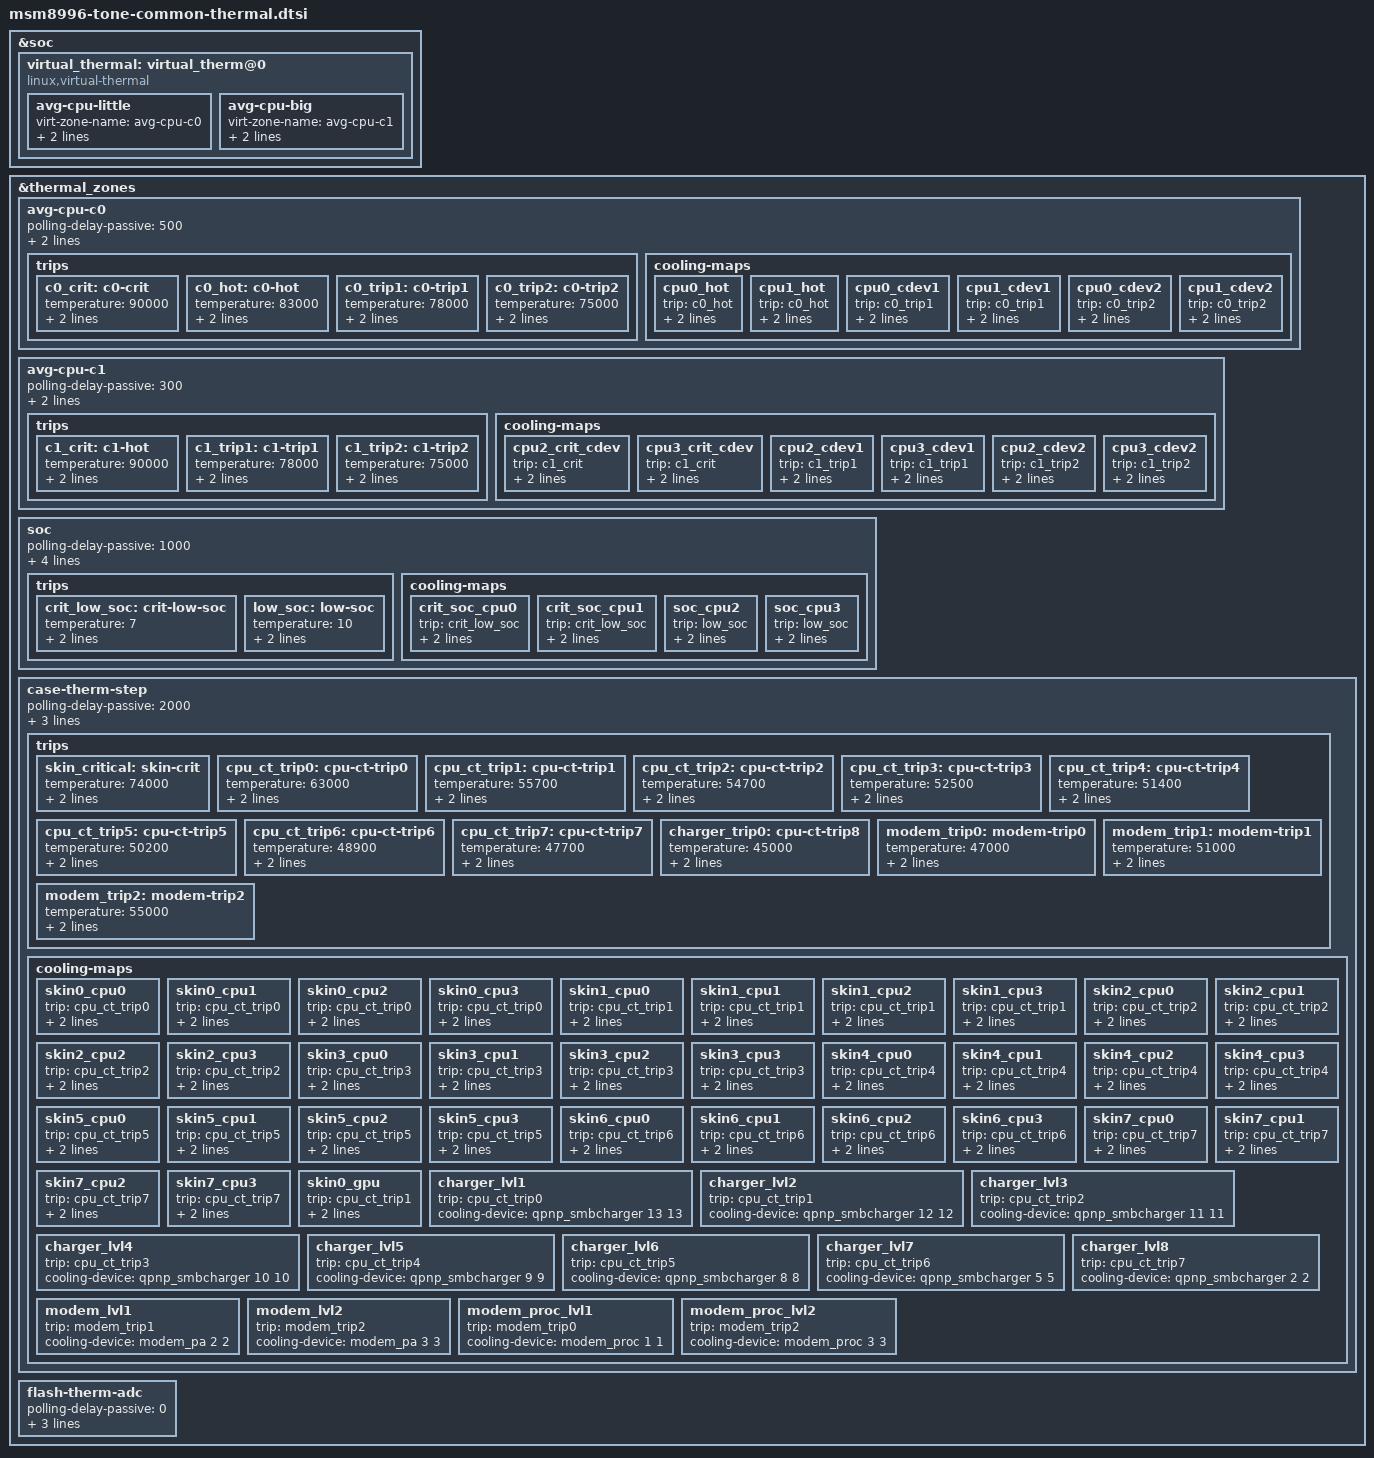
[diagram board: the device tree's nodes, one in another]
/* arch/arm64/boot/dts/qcom/msm8996-tone-common-thermal.dtsi
 *
 * This program is free software; you can redistribute it and/or modify
 * it under the terms of the GNU General Public License version 2 and
 * only version 2 as published by the Free Software Foundation.
 *
 * This program is distributed in the hope that it will be useful,
 * but WITHOUT ANY WARRANTY; without even the implied warranty of
 * MERCHANTABILITY or FITNESS FOR A PARTICULAR PURPOSE.  See the
 * GNU General Public License for more details.
 */
/*
 * Copyright (C) 2018 AngeloGioacchino Del Regno <kholk11@gmail.com>
 *
 * This program is free software; you can redistribute it and/or modify
 * it under the terms of the GNU General Public License version 2, as
 * published by the Free Software Foundation.
 */

&soc {
	virtual_thermal: virtual_therm@0 {
		compatible = "linux,virtual-thermal";
		status = "ok";
	};
};

&virtual_thermal {
	avg-cpu-little {
		virt-zone-name = "avg-cpu-c0";
		thermal-sensor-names = "cpu0-usr", "cpu1-usr";
		aggregation-logic = <0>; /* WEIGHTED_AVG */
	};
	avg-cpu-big {
		virt-zone-name = "avg-cpu-c1";
		thermal-sensor-names = "cpu2-usr", "cpu3-usr";
		aggregation-logic = <0>; /* WEIGHTED_AVG */
	};
};

&thermal_zones {
	avg-cpu-c0 {
		polling-delay-passive = <500>;
		polling-delay = <750>;
		thermal-governor = "step_wise";
		trips {
			c0_crit: c0-crit {
				temperature = <90000>;
				hysteresis = <4000>;
				type = "critical";
			};

			c0_hot: c0-hot {
				temperature = <83000>;
				hysteresis = <4000>;
				type = "hot";
			};

			c0_trip1: c0-trip1 {
				temperature = <78000>;
				hysteresis = <3000>;
				type = "passive";
				
			};

			c0_trip2: c0-trip2 {
				temperature = <75000>;
				hysteresis = <4000>;
				type = "passive";
				
			};
		};

		cooling-maps {
			/* Throttle from FMAX to 403.2MHz */
			cpu0_hot {
				trip = <&c0_hot>;
				cooling-device =
					<&CPU0 THERMAL_NO_LIMIT
						(THERMAL_MAX_LIMIT-3)>;
			};
			cpu1_hot {
				trip = <&c0_hot>;
				cooling-device =
					<&CPU1 THERMAL_NO_LIMIT
						(THERMAL_MAX_LIMIT-3)>;
			};

			/* Throttle from FMAX to 1267.2MHz */
			cpu0_cdev1 {
				trip = <&c0_trip1>;
				cooling-device =
					<&CPU0 THERMAL_NO_LIMIT
						(THERMAL_MAX_LIMIT-14)>;
			};
			cpu1_cdev1 {
				trip = <&c0_trip1>;
				cooling-device =
					<&CPU1 THERMAL_NO_LIMIT
						(THERMAL_MAX_LIMIT-14)>;
			};

			/* Throttle from FMAX to 1420.8MHz */
			cpu0_cdev2 {
				trip = <&c0_trip2>;
				cooling-device =
					<&CPU0 THERMAL_NO_LIMIT
						(THERMAL_MAX_LIMIT-16)>;
			};
			cpu1_cdev2 {
				trip = <&c0_trip2>;
				cooling-device =
					<&CPU1 THERMAL_NO_LIMIT
						(THERMAL_MAX_LIMIT-16)>;
			};

		};
	};

	avg-cpu-c1 {
		polling-delay-passive = <300>;
		polling-delay = <500>;
		thermal-governor = "step_wise";
		trips {
			c1_crit: c1-hot {
				temperature = <90000>;
				hysteresis = <4000>;
				type = "hot";
			};

			c1_trip1: c1-trip1 {
				temperature = <78000>;
				hysteresis = <3000>;
				type = "passive";
				
			};

			c1_trip2: c1-trip2 {
				temperature = <75000>;
				hysteresis = <4000>;
				type = "passive";
				
			};
		};

		cooling-maps {
			/* Temperature is critical: Shut down C1 */
			cpu2_crit_cdev {
				trip = <&c1_crit>;
				cooling-device =
					<&CPU2 THERMAL_MAX_LIMIT
						THERMAL_MAX_LIMIT>;
			};
			cpu3_crit_cdev {
				trip = <&c1_crit>;
				cooling-device =
					<&CPU3 THERMAL_MAX_LIMIT
						THERMAL_MAX_LIMIT>;
			};

			/* Throttle from FMAX to 1113.6MHz */
			cpu2_cdev1 {
				trip = <&c1_trip1>;
				cooling-device =
					<&CPU2 THERMAL_NO_LIMIT
						(THERMAL_MAX_LIMIT-12)>;
			};
			cpu3_cdev1 {
				trip = <&c1_trip1>;
				cooling-device =
					<&CPU3 THERMAL_NO_LIMIT
						(THERMAL_MAX_LIMIT-12)>;
			};

			/* Throttle from FMAX to 883.2MHz */
			cpu2_cdev2 {
				trip = <&c1_trip2>;
				cooling-device =
					<&CPU2 THERMAL_NO_LIMIT
						(THERMAL_MAX_LIMIT-9)>;
			};
			cpu3_cdev2 {
				trip = <&c1_trip2>;
				cooling-device =
					<&CPU3 THERMAL_NO_LIMIT
						(THERMAL_MAX_LIMIT-9)>;
			};
		};
	};

	soc {
		polling-delay-passive = <1000>;
		polling-delay = <0>;
		thermal-governor = "low_limits_cap";
		thermal-sensors = <&bcl_sensor 2>;
		tracks-low;

		trips {
			crit_low_soc: crit-low-soc {
				temperature = <7>;
				hysteresis = <0>;
				type = "passive";
			};
			low_soc: low-soc {
				temperature = <10>;
				hysteresis = <0>;
				type = "passive";
			};
		};

		cooling-maps {
			/* Throttle C0 from FMAX to 1190.4MHz */
			crit_soc_cpu0 {
				trip = <&crit_low_soc>;
				cooling-device =
					<&CPU0 THERMAL_NO_LIMIT
						(THERMAL_MAX_LIMIT-12)>;
			};
			crit_soc_cpu1 {
				trip = <&crit_low_soc>;
				cooling-device =
					<&CPU1 THERMAL_NO_LIMIT
						(THERMAL_MAX_LIMIT-12)>;
			};

			/* Shut down C1 */
			soc_cpu2 {
				trip = <&low_soc>;
				cooling-device =
					<&CPU2 THERMAL_MAX_LIMIT
						THERMAL_MAX_LIMIT>;
			};
			soc_cpu3 {
				trip = <&low_soc>;
				cooling-device =
					<&CPU3 THERMAL_MAX_LIMIT
						THERMAL_MAX_LIMIT>;
			};
		};
	};

	case-therm-step {
		polling-delay-passive = <2000>;
		polling-delay = <0>;
		thermal-sensors = <&pm8994_vadc 0x74>;
		thermal-governor = "step_wise";

		trips {
			skin_critical: skin-crit {
				temperature = <74000>;
				hysteresis = <2000>;
				type = "critical";
			};

			cpu_ct_trip0: cpu-ct-trip0 {
				temperature = <63000>;
				hysteresis = <3000>;
				type = "passive";
			};
			cpu_ct_trip1: cpu-ct-trip1 {
				temperature = <55700>;
				hysteresis = <1000>;
				type = "passive";
			};
			cpu_ct_trip2: cpu-ct-trip2 {
				temperature = <54700>;
				hysteresis = <1200>;
				type = "passive";
			};
			cpu_ct_trip3: cpu-ct-trip3 {
				temperature = <52500>;
				hysteresis = <1100>;
				type = "passive";
			};
			cpu_ct_trip4: cpu-ct-trip4 {
				temperature = <51400>;
				hysteresis = <1200>;
				type = "passive";
			};
			cpu_ct_trip5: cpu-ct-trip5 {
				temperature = <50200>;
				hysteresis = <300>;
				type = "passive";
			};
			cpu_ct_trip6: cpu-ct-trip6 {
				temperature = <48900>;
				hysteresis = <1200>;
				type = "passive";
			};
			cpu_ct_trip7: cpu-ct-trip7 {
				temperature = <47700>;
				hysteresis = <2700>;
				type = "passive";
			};

			charger_trip0: cpu-ct-trip8 {
				temperature = <45000>;
				hysteresis = <3000>;
				type = "passive";
			};

			modem_trip0: modem-trip0 {
				temperature = <47000>;
				hysteresis = <2000>;
				type = "passive";
			};
			modem_trip1: modem-trip1 {
				temperature = <51000>;
				hysteresis = <3000>;
				type = "passive";
			};
			modem_trip2: modem-trip2 {
				temperature = <55000>;
				hysteresis = <4000>;
				type = "passive";
			};
		};

		cooling-maps {
			/* Throttle from FMAX to 307.2MHz */
			skin0_cpu0 {
				trip = <&cpu_ct_trip0>;
				cooling-device = <&CPU0 THERMAL_NO_LIMIT
							(THERMAL_MAX_LIMIT-1)>;
			};
			skin0_cpu1 {
				trip = <&cpu_ct_trip0>;
				cooling-device = <&CPU1 THERMAL_NO_LIMIT
							(THERMAL_MAX_LIMIT-1)>;
			};
			/* Reaching critical: shutdown C1 */
			skin0_cpu2 {
				trip = <&cpu_ct_trip0>;
				cooling-device = <&CPU2 THERMAL_NO_LIMIT
							THERMAL_MAX_LIMIT>;
			};
			skin0_cpu3 {
				trip = <&cpu_ct_trip0>;
				cooling-device = <&CPU3 THERMAL_NO_LIMIT
							THERMAL_MAX_LIMIT>;
			};

			/* Throttle from FMAX to 307.2MHz */
			skin1_cpu0 {
				trip = <&cpu_ct_trip1>;
				cooling-device = <&CPU0 THERMAL_NO_LIMIT
							(THERMAL_MAX_LIMIT-1)>;
			};
			skin1_cpu1 {
				trip = <&cpu_ct_trip1>;
				cooling-device = <&CPU1 THERMAL_NO_LIMIT
							(THERMAL_MAX_LIMIT-1)>;
			};
			skin1_cpu2 {
				trip = <&cpu_ct_trip1>;
				cooling-device = <&CPU2 THERMAL_NO_LIMIT
							(THERMAL_MAX_LIMIT-1)>;
			};
			skin1_cpu3 {
				trip = <&cpu_ct_trip1>;
				cooling-device = <&CPU3 THERMAL_NO_LIMIT
							(THERMAL_MAX_LIMIT-1)>;
			};

			/* Throttle from FMAX to 480MHz */
			skin2_cpu0 {
				trip = <&cpu_ct_trip2>;
				cooling-device = <&CPU0 THERMAL_NO_LIMIT
							(THERMAL_MAX_LIMIT-4)>;
			};
			skin2_cpu1 {
				trip = <&cpu_ct_trip2>;
				cooling-device = <&CPU1 THERMAL_NO_LIMIT
							(THERMAL_MAX_LIMIT-4)>;
			};
			skin2_cpu2 {
				trip = <&cpu_ct_trip2>;
				cooling-device = <&CPU2 THERMAL_NO_LIMIT
							(THERMAL_MAX_LIMIT-4)>;
			};
			skin2_cpu3 {
				trip = <&cpu_ct_trip2>;
				cooling-device = <&CPU3 THERMAL_NO_LIMIT
							(THERMAL_MAX_LIMIT-4)>;
			};

			/* Throttle from FMAX to 883.2MHz */
			skin3_cpu0 {
				trip = <&cpu_ct_trip3>;
				cooling-device = <&CPU0 THERMAL_NO_LIMIT
							(THERMAL_MAX_LIMIT-9)>;
			};
			skin3_cpu1 {
				trip = <&cpu_ct_trip3>;
				cooling-device = <&CPU1 THERMAL_NO_LIMIT
							(THERMAL_MAX_LIMIT-9)>;
			};
			skin3_cpu2 {
				trip = <&cpu_ct_trip3>;
				cooling-device = <&CPU2 THERMAL_NO_LIMIT
							(THERMAL_MAX_LIMIT-9)>;
			};
			skin3_cpu3 {
				trip = <&cpu_ct_trip3>;
				cooling-device = <&CPU3 THERMAL_NO_LIMIT
							(THERMAL_MAX_LIMIT-9)>;
			};

			/* Throttle from FMAX to 1017.6MHz */
			skin4_cpu0 {
				trip = <&cpu_ct_trip4>;
				cooling-device = <&CPU0 THERMAL_NO_LIMIT
							(THERMAL_MAX_LIMIT-11)>;
			};
			skin4_cpu1 {
				trip = <&cpu_ct_trip4>;
				cooling-device = <&CPU1 THERMAL_NO_LIMIT
							(THERMAL_MAX_LIMIT-11)>;
			};
			skin4_cpu2 {
				trip = <&cpu_ct_trip4>;
				cooling-device = <&CPU2 THERMAL_NO_LIMIT
							(THERMAL_MAX_LIMIT-11)>;
			};
			skin4_cpu3 {
				trip = <&cpu_ct_trip4>;
				cooling-device = <&CPU3 THERMAL_NO_LIMIT
							(THERMAL_MAX_LIMIT-11)>;
			};

			/* Throttle from FMAX to 1113.6MHz */
			skin5_cpu0 {
				trip = <&cpu_ct_trip5>;
				cooling-device = <&CPU0 THERMAL_NO_LIMIT
							(THERMAL_MAX_LIMIT-12)>;
			};
			skin5_cpu1 {
				trip = <&cpu_ct_trip5>;
				cooling-device = <&CPU1 THERMAL_NO_LIMIT
							(THERMAL_MAX_LIMIT-12)>;
			};
			skin5_cpu2 {
				trip = <&cpu_ct_trip5>;
				cooling-device = <&CPU2 THERMAL_NO_LIMIT
							(THERMAL_MAX_LIMIT-12)>;
			};
			skin5_cpu3 {
				trip = <&cpu_ct_trip5>;
				cooling-device = <&CPU3 THERMAL_NO_LIMIT
							(THERMAL_MAX_LIMIT-12)>;
			};

			/* Throttle from FMAX to 1344MHz */
			skin6_cpu0 {
				trip = <&cpu_ct_trip6>;
				cooling-device = <&CPU0 THERMAL_NO_LIMIT
							(THERMAL_MAX_LIMIT-15)>;
			};
			skin6_cpu1 {
				trip = <&cpu_ct_trip6>;
				cooling-device = <&CPU1 THERMAL_NO_LIMIT
							(THERMAL_MAX_LIMIT-15)>;
			};
			skin6_cpu2 {
				trip = <&cpu_ct_trip6>;
				cooling-device = <&CPU2 THERMAL_NO_LIMIT
							(THERMAL_MAX_LIMIT-15)>;
			};
			skin6_cpu3 {
				trip = <&cpu_ct_trip6>;
				cooling-device = <&CPU3 THERMAL_NO_LIMIT
							(THERMAL_MAX_LIMIT-15)>;
			};

			/* Throttle from C0-C1 FMAX to 1459.2-1497.6MHz */
			skin7_cpu0 {
				trip = <&cpu_ct_trip7>;
				cooling-device = <&CPU0 THERMAL_NO_LIMIT
							(THERMAL_MAX_LIMIT-17)>;
			};
			skin7_cpu1 {
				trip = <&cpu_ct_trip7>;
				cooling-device = <&CPU1 THERMAL_NO_LIMIT
							(THERMAL_MAX_LIMIT-17)>;
			};
			skin7_cpu2 {
				trip = <&cpu_ct_trip7>;
				cooling-device = <&CPU2 THERMAL_NO_LIMIT
							(THERMAL_MAX_LIMIT-17)>;
			};
			skin7_cpu3 {
				trip = <&cpu_ct_trip7>;
				cooling-device = <&CPU3 THERMAL_NO_LIMIT
							(THERMAL_MAX_LIMIT-17)>;
			};

			/* Throttle from FMAX to 133MHz */
			skin0_gpu {
				trip = <&cpu_ct_trip1>;
				cooling-device = <&msm_gpu THERMAL_NO_LIMIT
							   (THERMAL_MAX_LIMIT-1)>;
			};

			/* Battery charging current limit */
			charger_lvl1 {
				trip = <&cpu_ct_trip0>;
				cooling-device = <&qpnp_smbcharger 13 13>;
			};
			charger_lvl2 {
				trip = <&cpu_ct_trip1>;
				cooling-device = <&qpnp_smbcharger 12 12>;
			};
			charger_lvl3 {
				trip = <&cpu_ct_trip2>;
				cooling-device = <&qpnp_smbcharger 11 11>;
			};
			charger_lvl4 {
				trip = <&cpu_ct_trip3>;
				cooling-device = <&qpnp_smbcharger 10 10>;
			};
			charger_lvl5 {
				trip = <&cpu_ct_trip4>;
				cooling-device = <&qpnp_smbcharger 9 9>;
			};
			charger_lvl6 {
				trip = <&cpu_ct_trip5>;
				cooling-device = <&qpnp_smbcharger 8 8>;
			};
			charger_lvl7 {
				trip = <&cpu_ct_trip6>;
				cooling-device = <&qpnp_smbcharger 5 5>;
			};
			charger_lvl8 {
				trip = <&cpu_ct_trip7>;
				cooling-device = <&qpnp_smbcharger 2 2>;
			};

			/* Modem PA power limit */
			modem_lvl1 {
				trip = <&modem_trip1>;
				cooling-device = <&modem_pa 2 2>;
			};
			modem_lvl2 {
				trip = <&modem_trip2>;
				cooling-device = <&modem_pa 3 3>;
			};

			/* Modem proc limit */
			modem_proc_lvl1 {
				trip = <&modem_trip0>;
				cooling-device = <&modem_proc 1 1>;
			};
			modem_proc_lvl2 {
				trip = <&modem_trip2>;
				cooling-device = <&modem_proc 3 3>;
			};
		};
	};

	flash-therm-adc {
		polling-delay-passive = <0>;
		polling-delay = <0>;
		thermal-sensors = <&pm8994_vadc 0x14>;
		thermal-governor = "user_space";
	};
};
